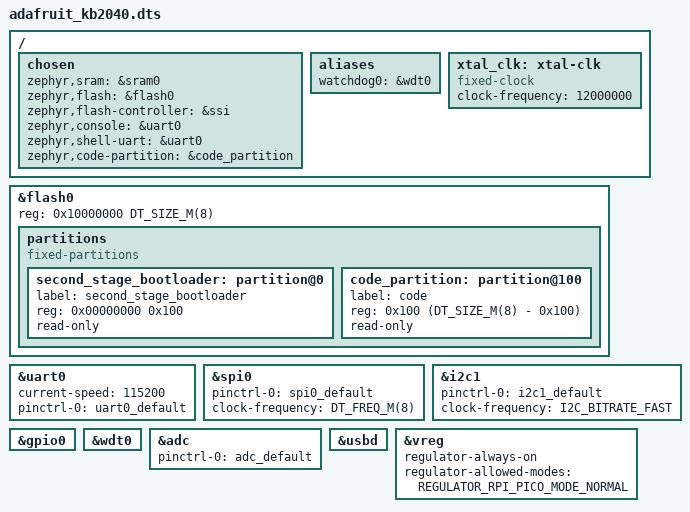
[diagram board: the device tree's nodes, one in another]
/*
 * Copyright (c) 2021 Yonatan Schachter
 * Copyright (c) 2022 Peter Johanson
 *
 * SPDX-License-Identifier: Apache-2.0
 */

/dts-v1/;

#include <rpi_pico/rp2040.dtsi>
#include "adafruit_kb2040-pinctrl.dtsi"
#include "sparkfun_pro_micro_connector.dtsi"
#include <freq.h>

/ {
	chosen {
		zephyr,sram = &sram0;
		zephyr,flash = &flash0;
		zephyr,flash-controller = &ssi;
		zephyr,console = &uart0;
		zephyr,shell-uart = &uart0;
		zephyr,code-partition = &code_partition;
	};

	aliases {
		watchdog0 = &wdt0;
	};

	xtal_clk: xtal-clk {
		compatible = "fixed-clock";
		clock-frequency = <12000000>;
		#clock-cells = <0>;
	};
};

&flash0 {
	reg = <0x10000000 DT_SIZE_M(8)>;

	partitions {
		compatible = "fixed-partitions";
		#address-cells = <1>;
		#size-cells = <1>;

		/* Reserved memory for the second stage bootloader */
		second_stage_bootloader: partition@0 {
			label = "second_stage_bootloader";
			reg = <0x00000000 0x100>;
			read-only;
		};

		/*
		 * Usable flash. Starts at 0x100, after the bootloader. The partition
		 * size is 8MB minus the 0x100 bytes taken by the bootloader.
		 */
		code_partition: partition@100 {
			label = "code";
			reg = <0x100 (DT_SIZE_M(8) - 0x100)>;
			read-only;
		};
	};
};

&uart0 {
	current-speed = <115200>;
	status = "okay";
	pinctrl-0 = <&uart0_default>;
	pinctrl-names = "default";
};

&spi0 {
	status = "okay";
	pinctrl-0 = <&spi0_default>;
	pinctrl-names = "default";
	clock-frequency = <DT_FREQ_M(8)>;
};

&i2c1 {
	status = "okay";
	pinctrl-0 = <&i2c1_default>;
	pinctrl-names = "default";
	clock-frequency = <I2C_BITRATE_FAST>;
};

&gpio0 {
	status = "okay";
};

&wdt0 {
	status = "okay";
};

&adc {
	status = "okay";
	pinctrl-0 = <&adc_default>;
	pinctrl-names = "default";
};

zephyr_udc0: &usbd {
	status = "okay";
};

&vreg {
	regulator-always-on;
	regulator-allowed-modes = <REGULATOR_RPI_PICO_MODE_NORMAL>;
};
